# M460 register map
File version: 1.0
Registers are 32-bit, read-write, reset 0x0 unless marked. A register's access mark holds for its fields unless they carry their own. Offsets are from the block's base; [hi:lo] are bit positions; {n}, {i} and the like mark numbered series; 'fields as' and 'values as' point back to an identical list.

## HMAC — CRYPTO Register Map
Base 0x40032300
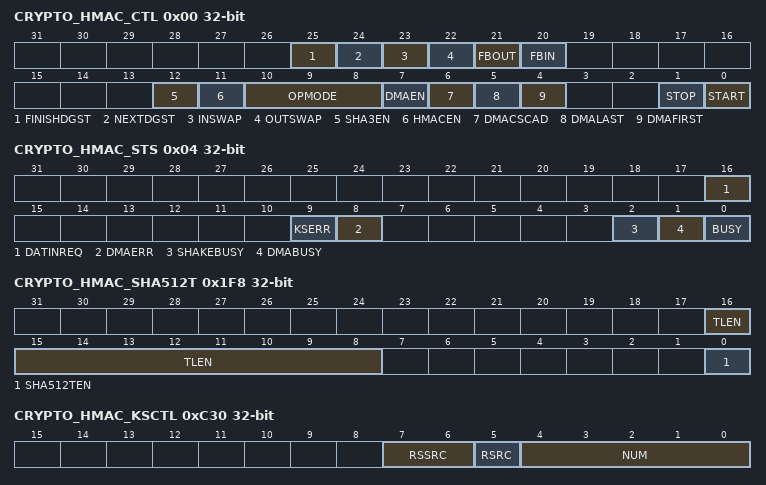
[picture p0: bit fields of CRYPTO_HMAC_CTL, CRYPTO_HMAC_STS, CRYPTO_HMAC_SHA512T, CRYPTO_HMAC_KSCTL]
0x00 CRYPTO_HMAC_CTL — SHA/HMAC Control Register
  [25] FINISHDGST — SHAKE128/256 Next Digest Finish
    0=No effect; 1=finish generating the next digest
  [24] NEXTDGST — SHAKE128/256 Next Digest Start
    0=No effect; 1=Start SHAKE engine to generate the next digest only when SHAKEBUSY is 0. BUSY and SHAKEBUSY flag will be set
  [23] INSWAP — SHA/HMAC Engine Input Data Swap
    0=Keep the original order; 1=The order that CPU feeds data to the accelerator will be changed from {byte3, byte2, byte1, byte0} to {byte0, byte1, byte2, byte3}
  [22] OUTSWAP — SHA/HMAC Engine Output Data Swap
    values as INSWAP
  [21] FBOUT — Feedback Output From SHA/HMAC Via DMA Automatically
    0=DMA automatic feedback output function Disabled; 1=DMA automatic feedback output function Enabled when DMAEN = 1
  [20] FBIN — Feedback Input to SHA/HMAC Via DMA Automatically
    0=DMA automatic feedback input function Disabled; 1=DMA automatic feedback input function Enabled when DMAEN = 1
  [12] SHA3EN — SHA3 Engine Enable Bit
    0=Execute other function; 1=Execute SHA3 function
  [11] HMACEN — HMAC_SHA Engine Operating Mode
    0=Execute SHA function; 1=Execute HMAC function
  [10:8] OPMODE — SHA/HMAC Engine Operation Modes. 0x100: SHA3-256. 0x101: SHA3-224. 0x110: SHA3-512. 0x111: SHA3-384. 0x000: SHAKE128. 0x001: SHAKE256. Note: These bits can be read and written. But writing to them wouldn't take effect as BUSY is 1.
  [7] DMAEN — SHA/HMAC Engine DMA Enable Bit. SHA/HMAC engine operates in DMA mode, and data movement from/to the engine is done by DMA logic.
    0=SHA/HMAC DMA engine Disabled; 1=SHA/HMAC DMA engine Enabled
  [6] DMACSCAD — SHA/HMAC Engine DMA with Cascade Mode
    0=DMA cascade function Disabled; 1=In DMA cascade mode, software can update DMA source address register, destination address register, and byte count register during a cascade operation, without finishing the accelerator operation
  [5] DMALAST — SHA/HMAC Last Block. This bit must be set as feeding in last byte of data.
  [4] DMAFIRST — SHA/HMAC First Block in Cascade function. This bit must be set as feeding in first byte of data.
  [1] STOP — SHA/HMAC Engine Stop. Note: This bit is always 0 when it is read back.
    0=No effect; 1=Stop SHA/HMAC engine
  [0] START — SHA/HMAC Engine Start. Note: This bit is always 0 when it is read back.
    0=No effect; 1=Start SHA/HMAC engine. BUSY flag will be set
0x04 CRYPTO_HMAC_STS ro — SHA/HMAC Status Flag
  [16] DATINREQ — SHA/HMAC Non-DMA Mode Data Input Request
    0=No effect; 1=Request SHA/HMAC Non-DMA mode data input
  [9] KSERR — HMAC Engine Access Key Store Error Flag
    0=No error; 1=Access error will stop HMAC engine
  [8] DMAERR — SHA/HMAC Engine DMA Error Flag
    0=Show the SHA/HMAC engine access normal; 1=Show the SHA/HMAC engine access error
  [2] SHAKEBUSY — SHAKE Engine Busy Flag
    0=SHAKE engine is idle or finished; 1=SHAKE engine is busy
  [1] DMABUSY — SHA/HMAC Engine DMA Busy Flag
    0=SHA/HMAC DMA engine is idle or finished; 1=SHA/HMAC DMA engine is busy
  [0] BUSY — SHA/HMAC Engine Busy
    0=SHA/HMAC engine is idle or finished; 1=SHA/HMAC engine is busy
{0x8+4i} CRYPTO_HMAC_DGST{i} ro (i=0..15) — SHA/HMAC Output Feedback Data {i}
  [31:0] DGST — SHA/HMAC Output Feedback Data Output Register. For SHA-160, the digest is stored in CRYPTO_HMAC_DGST0 ~ CRYPTO_HMAC_DGST4. For SHA-224, the digest is stored in CRYPTO_HMAC_DGST0 ~ CRYPTO_HMAC_DGST6. For SHA-256, the digest is stored in CRYPTO_HMAC_DGST0 ~ CRYPTO_HMAC_DGST7. For SHA-384, the digest is stored in CRYPTO_HMAC_DGST0 ~ CRYPTO_HMAC_DGST11. For SHA-512, the digest is stored in CRYPTO_HMAC_DGST0 ~ CRYPTO_HMAC_DGST15.
0x48 CRYPTO_HMAC_KEYCNT — SHA/HMAC Key Byte Count Register
  [31:0] KEYCNT — SHA/HMAC Key Byte Count. The CRYPTO_HMAC_KEYCNT keeps the byte count of key that SHA/HMAC engine operates. The register is 32-bit and the maximum byte count is 4G bytes. It can be read and written. Writing to the register CRYPTO_HMAC_KEYCNT as the SHA/HMAC accelerator operating doesn't affect the current SHA/HMAC operation. But the value of CRYPTO_HMAC_KEYCNT will be updated later on. Consequently, software can prepare the key count for the next SHA/HMAC operation.
0x4C CRYPTO_HMAC_SADDR — SHA/HMAC DMA Source Address Register
  [31:0] SADDR — SHA/HMAC DMA Source Address. The SHA/HMAC accelerator supports DMA function to transfer the plain text between SRAM memory space and embedded FIFO. The CRYPTO_HMAC_SADDR keeps the source address of the data buffer where the source text is stored. Based on the source address, the SHA/HMAC accelerator can read the plain text from SRAM memory space and do SHA/HMAC operation. The start of source address should be located at word boundary. In other words, bit 1 and 0 of CRYPTO_HMAC_SADDR are ignored. CRYPTO_HMAC_SADDR can be read and written. Writing to CRYPTO_HMAC_SADDR while the SHA/HMAC accelerator is operating doesn't affect the current SHA/HMAC operation. But the value of CRYPTO_HMAC_SADDR will be updated later on. Consequently, software can prepare the DMA source address for the next SHA/HMAC operation. In DMA mode, software can update the next CRYPTO_HMAC_SADDR before triggering START. CRYPTO_HMAC_SADDR and CRYPTO_HMAC_DADDR can be the same in the value.
0x50 CRYPTO_HMAC_DMACNT — SHA/HMAC Byte Count Register
  [31:0] DMACNT — SHA/HMAC Operation Byte Count. The CRYPTO_HMAC_DMACNT keeps the byte count of source text that is for the SHA/HMAC engine operating in DMA mode. The CRYPTO_HMAC_DMACNT is 32-bit and the maximum of byte count is 4G bytes. CRYPTO_HMAC_DMACNT can be read and written. Writing to CRYPTO_HMAC_DMACNT while the SHA/HMAC accelerator is operating doesn't affect the current SHA/HMAC operation. But the value of CRYPTO_HMAC_DMACNT will be updated later on. Consequently, software can prepare the byte count of data for the next SHA/HMAC operation. In Non-DMA mode, CRYPTO_HMAC_DMACNT must be set as the byte count of the last block before feeding in the last block of data.
0x54 CRYPTO_HMAC_DATIN — SHA/HMAC Engine Non-DMA Mode Data Input Port Register
  [31:0] DATIN — SHA/HMAC Engine Input Port. CPU feeds data to SHA/HMAC engine through this port by checking CRYPTO_HMAC_STS. Feed data as DATINREQ is 1.
{0x58+4i} CRYPTO_HMAC_FDBCK{i} (i=0..87) — SHA/HMAC Output Feedback Data {i} After SHA/HMAC Operation
  [31:0] FDBCK — SHA/HMAC Feedback Information. The feedback value is 1728 bits in size for SHA1/2 and 2784 bits in size for SHA3. The SHA/HMAC engine uses the data from CRYPTO_HMAC_FDBCKx as the data inputted to CRYPTO_HMAC_FDBCKx for the next block in DMA cascade mode. The SHA/HMAC engine outputs feedback information for initial setting in the next block's operation. Software can store that feedback value temporarily. After switching back, fill the stored feedback value to CRYPTO_HMAC_FDBCKx in the same operation, and then continue the operation with the original setting.
0x1F8 CRYPTO_HMAC_SHA512T — SHA/HMAC SHA512/t Control Register
  [16:8] TLEN — SHA512/t output digest length. The TLEN is equal to value t of SHA512/t. It also means the output digest length of SHA512 /t. Note: TLEN 512, and TLEN is not 384.
  [0] SHA512TEN — SHA512/t Engine Enable Bit
    0=Execute other function; 1=Execute SHA512/t function if SHA3EN=0
0x1FC CRYPTO_HMAC_FBADDR — SHA/HMAC DMA Feedback Address Register
  [31:0] FBADDR — SHA/HMAC DMA Feedback Address. In DMA cascade mode, software can update DMA feedback address register for automatically reading and writing feedback values via DMA. The FBADDR keeps the feedback address of the feedback data for the next cascade operation. Based on the feedback address, the SHA/HMAC accelerator can read the feedback data of the last cascade operation from SRAM memory space and write the feedback data of the current cascade operation to SRAM memory space. The start of feedback address should be located at word boundary. In other words, bit 1 and 0 of FBADDR are ignored. FBADDR can be read and written. In DMA mode, software can update the next CRYPTO_HMAC_FBADDR before triggering START.
{0x200+4i} CRYPTO_HMAC_SHAKEDGST{i} ro (i=0..41) — SHA/HMAC SHAKE Digest Message {i}
  [31:0] DGST — SHA/HMAC SHAKE Digest Message Register. For SHAKE-128, the digest is stored in CRYPTO_HMAC_SHAKEDGST0 0 ~ CRYPTO_HMAC_ SHAKEDGST0 41. For SHAKE-256, the digest is stored in CRYPTO_HMAC_SHAKEDGST0 0 ~ CRYPTO_HMAC_ SHAKEDGST0 33.
0xC30 CRYPTO_HMAC_KSCTL wo — HMAC Key Control Register
  [7:6] RSSRC — Read Key Store Source
    0=Key is read from the SRAM of key store; 1=Key is read from the Flash of key store; 2=Key is read from the OTP of key store
  [5] RSRC — Read Key Source
    0=Key is read from HMAC registers; 1=Key is read from key store
  [4:0] NUM — Read Key Number. The key number is sent to key store
